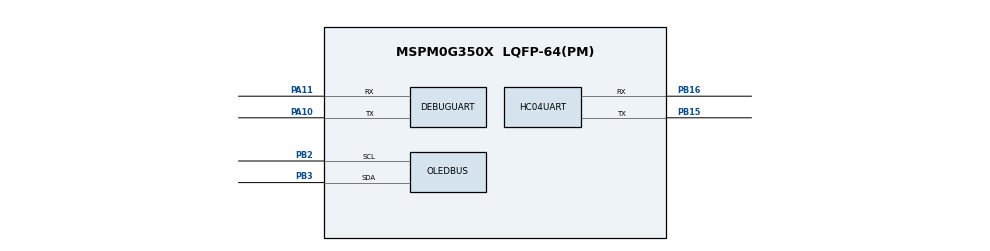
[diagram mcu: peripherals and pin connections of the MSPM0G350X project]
/**
 * @cliArgs --device "MSPM0G350X" --part "Default" --package "LQFP-64(PM)" --product "mspm0_sdk@2.10.00.04"
 * @versions {"tool":"1.26.2+4477"}
 */
const UART      = scripting.addModule("/ti/driverlib/UART", {}, false);
const DEBUGUART = UART.addInstance();
const HC04UART  = UART.addInstance();
const I2C       = scripting.addModule("/ti/driverlib/I2C", {}, false);
const OLEDBUS   = I2C.addInstance();
const SYSCTL    = scripting.addModule("/ti/driverlib/SYSCTL");

DEBUGUART.$name                    = "DEBUG_UART";
DEBUGUART.profile                  = "CONFIG_PROFILE_1";
DEBUGUART.peripheral.$assign       = "UART0";
DEBUGUART.targetBaudRate           = 9600;
DEBUGUART.enableInternalLoopback   = false;
DEBUGUART.enableFIFO               = false;
DEBUGUART.peripheral.rxPin.$assign = "PA11";
DEBUGUART.peripheral.txPin.$assign = "PA10";

HC04UART.$name                    = "HC04_UART";
HC04UART.profile                  = "CONFIG_PROFILE_1";
HC04UART.peripheral.$assign       = "UART2";
HC04UART.targetBaudRate           = 9600;
HC04UART.enableInternalLoopback   = false;
HC04UART.enabledInterrupts        = ["RX"];
HC04UART.enableFIFO               = false;
HC04UART.peripheral.rxPin.$assign = "PB16";
HC04UART.peripheral.txPin.$assign = "PB15";

OLEDBUS.$name                     = "I2C";
OLEDBUS.peripheral.$assign        = "I2C1";
OLEDBUS.basicEnableController     = true;
OLEDBUS.basicControllerBusSpeed   = 400000;
OLEDBUS.advAnalogGlitchFilter     = "DISABLED";
OLEDBUS.peripheral.sclPin.$assign = "PB2";
OLEDBUS.peripheral.sdaPin.$assign = "PB3";

const Board = scripting.addModule("/ti/driverlib/Board", {}, false);

SYSCTL.forceDefaultClkConfig = true;
Board.peripheral.$suggestSolution          = "DEBUGSS";
Board.peripheral.swclkPin.$suggestSolution = "PA20";
Board.peripheral.swdioPin.$suggestSolution = "PA19";
SYSCTL.peripheral.$suggestSolution         = "SYSCTL";
